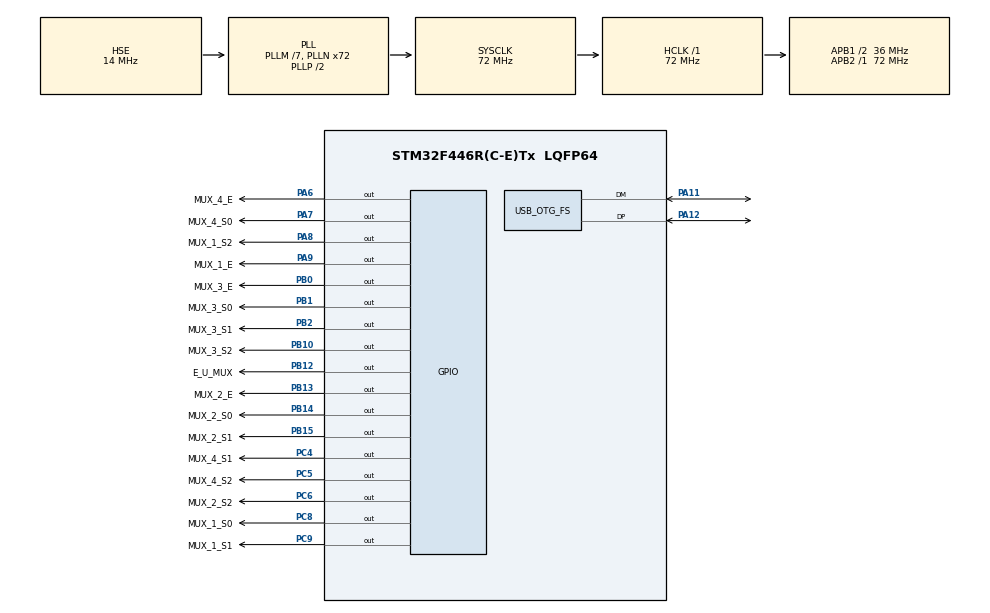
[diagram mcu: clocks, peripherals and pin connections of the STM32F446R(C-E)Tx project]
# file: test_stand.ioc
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Mcu.Family=STM32F4
Mcu.Name=STM32F446R(C-E)Tx
Mcu.Package=LQFP64
NVIC.OTG_FS_IRQn=true\:0\:0\:false\:false\:true\:false\:true\:true
NVIC.PriorityGroup=NVIC_PRIORITYGROUP_4
PA11.Mode=Device_Only
PA11.Signal=USB_OTG_FS_DM
PA12.Mode=Device_Only
PA12.Signal=USB_OTG_FS_DP
PA13.Mode=JTAG_5_pins
PA13.Signal=SYS_JTMS-SWDIO
PA14.Mode=JTAG_5_pins
PA14.Signal=SYS_JTCK-SWCLK
PA15.Mode=JTAG_5_pins
PA15.Signal=SYS_JTDI
PA6.GPIO_Label=MUX_4_E
PA6.Signal=GPIO_Output
PA7.GPIO_Label=MUX_4_S0
PA7.Signal=GPIO_Output
PA8.GPIO_Label=MUX_1_S2
PA8.Signal=GPIO_Output
PA9.GPIO_Label=MUX_1_E
PA9.Signal=GPIO_Output
PB0.GPIO_Label=MUX_3_E
PB0.Signal=GPIO_Output
PB1.GPIO_Label=MUX_3_S0
PB1.Signal=GPIO_Output
PB10.GPIO_Label=MUX_3_S2
PB10.Signal=GPIO_Output
PB12.GPIO_Label=E_U_MUX
PB12.Signal=GPIO_Output
PB13.GPIO_Label=MUX_2_E
PB13.Signal=GPIO_Output
PB14.GPIO_Label=MUX_2_S0
PB14.Signal=GPIO_Output
PB15.GPIO_Label=MUX_2_S1
PB15.Signal=GPIO_Output
PB2.GPIO_Label=MUX_3_S1
PB2.Signal=GPIO_Output
PB3.Mode=JTAG_5_pins
PB3.Signal=SYS_JTDO-SWO
PB4.Mode=JTAG_5_pins
PB4.Signal=SYS_JTRST
PC4.GPIO_Label=MUX_4_S1
PC4.Signal=GPIO_Output
PC5.GPIO_Label=MUX_4_S2
PC5.Signal=GPIO_Output
PC6.GPIO_Label=MUX_2_S2
PC6.Signal=GPIO_Output
PC8.GPIO_Label=MUX_1_S0
PC8.Signal=GPIO_Output
PC9.GPIO_Label=MUX_1_S1
PC9.Signal=GPIO_Output
PH0-OSC_IN.Mode=HSE-External-Oscillator
PH0-OSC_IN.Signal=RCC_OSC_IN
PH1-OSC_OUT.Mode=HSE-External-Oscillator
PH1-OSC_OUT.Signal=RCC_OSC_OUT
ProjectManager.HeapSize=0x200
ProjectManager.StackSize=0x400
ProjectManager.TargetToolchain=STM32CubeIDE
RCC.AHBFreq_Value=72000000
RCC.APB1CLKDivider=RCC_HCLK_DIV2
RCC.APB1Freq_Value=36000000
RCC.APB1TimFreq_Value=72000000
RCC.APB2Freq_Value=72000000
RCC.APB2TimFreq_Value=72000000
RCC.CortexFreq_Value=72000000
RCC.HCLKFreq_Value=72000000
RCC.HSE_VALUE=14000000
RCC.PLLM=7
RCC.PLLN=72
RCC.PLLQ=3
RCC.PLLSourceVirtual=RCC_PLLSOURCE_HSE
RCC.SYSCLKFreq_VALUE=72000000
RCC.SYSCLKSource=RCC_SYSCLKSOURCE_PLLCLK
RCC.USBFreq_Value=48000000
RCC.VCOOutputFreq_Value=144000000
USB_DEVICE.CLASS_NAME_FS=CDC
USB_DEVICE.VirtualMode-CDC_FS=Cdc
USB_DEVICE.VirtualModeFS=Cdc_FS
USB_OTG_FS.VirtualMode=Device_Only
VP_USB_DEVICE_VS_USB_DEVICE_CDC_FS.Mode=CDC_FS
board=custom

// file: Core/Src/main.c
/* USER CODE BEGIN Header */
/**
  ******************************************************************************
  * @file           : main.c
  * @brief          : Main program body
  ******************************************************************************
  * @attention
  *
  * Copyright (c) 2024 STMicroelectronics.
  * All rights reserved.
  *
  * This software is licensed under terms that can be found in the LICENSE file
  * in the root directory of this software component.
  * If no LICENSE file comes with this software, it is provided AS-IS.
  *
  ******************************************************************************
  */
/* USER CODE END Header */
#include "main.h"
#include "usb_device.h"
#include "gpio.h"

/* USER CODE BEGIN Includes */
#include "usbd_cdc_if.h"
/* USER CODE END Includes */

/* USER CODE BEGIN PV */
// ответ на запрос
uint8_t ID[1]={0xBB};

// ответ на команду включения, что мы не зависли и отвечаем
uint8_t ANTWORT[1]={0xEE};

// входной буфер
uint8_t RxData[1] = {0};

/* USER CODE END PV */

void SystemClock_Config(void);

int main(void)
{

  /* MCU Configuration--------------------------------------------------------*/

  /* Reset of all peripherals, Initializes the Flash interface and the Systick. */
  HAL_Init();

  /* Configure the system clock */
  SystemClock_Config();

  /* Initialize all configured peripherals */
  MX_GPIO_Init();
  MX_USB_DEVICE_Init();

  /* Infinite loop */
  while (1)
  {

    /* USER CODE BEGIN 3 */
	  HAL_Delay(100);
	  HAL_GPIO_TogglePin(E_U_MUX_GPIO_Port, E_U_MUX_Pin);
	  CDC_Receive_FS(RxData,  (uint32_t)1);
	  CDC_Transmit_FS(ANTWORT, 1);

  }
  /* USER CODE END 3 */
}

void SystemClock_Config(void)
{
  RCC_OscInitTypeDef RCC_OscInitStruct = {0};
  RCC_ClkInitTypeDef RCC_ClkInitStruct = {0};

  /** Configure the main internal regulator output voltage
  */
  __HAL_RCC_PWR_CLK_ENABLE();
  __HAL_PWR_VOLTAGESCALING_CONFIG(PWR_REGULATOR_VOLTAGE_SCALE3);

  /** Initializes the RCC Oscillators according to the specified parameters
  * in the RCC_OscInitTypeDef structure.
  */
  RCC_OscInitStruct.OscillatorType = RCC_OSCILLATORTYPE_HSE;
  RCC_OscInitStruct.HSEState = RCC_HSE_ON;
  RCC_OscInitStruct.PLL.PLLState = RCC_PLL_ON;
  RCC_OscInitStruct.PLL.PLLSource = RCC_PLLSOURCE_HSE;
  RCC_OscInitStruct.PLL.PLLM = 7;
  RCC_OscInitStruct.PLL.PLLN = 72;
  RCC_OscInitStruct.PLL.PLLP = RCC_PLLP_DIV2;
  RCC_OscInitStruct.PLL.PLLQ = 3;
  RCC_OscInitStruct.PLL.PLLR = 2;
  if (HAL_RCC_OscConfig(&RCC_OscInitStruct) != HAL_OK)
  {
    Error_Handler();
  }

  /** Initializes the CPU, AHB and APB buses clocks
  */
  RCC_ClkInitStruct.ClockType = RCC_CLOCKTYPE_HCLK|RCC_CLOCKTYPE_SYSCLK
                              |RCC_CLOCKTYPE_PCLK1|RCC_CLOCKTYPE_PCLK2;
  RCC_ClkInitStruct.SYSCLKSource = RCC_SYSCLKSOURCE_PLLCLK;
  RCC_ClkInitStruct.AHBCLKDivider = RCC_SYSCLK_DIV1;
  RCC_ClkInitStruct.APB1CLKDivider = RCC_HCLK_DIV2;
  RCC_ClkInitStruct.APB2CLKDivider = RCC_HCLK_DIV1;

  if (HAL_RCC_ClockConfig(&RCC_ClkInitStruct, FLASH_LATENCY_2) != HAL_OK)
  {
    Error_Handler();
  }
}

void Error_Handler(void)
{
  __disable_irq();
  while (1)
  {
  }
}
